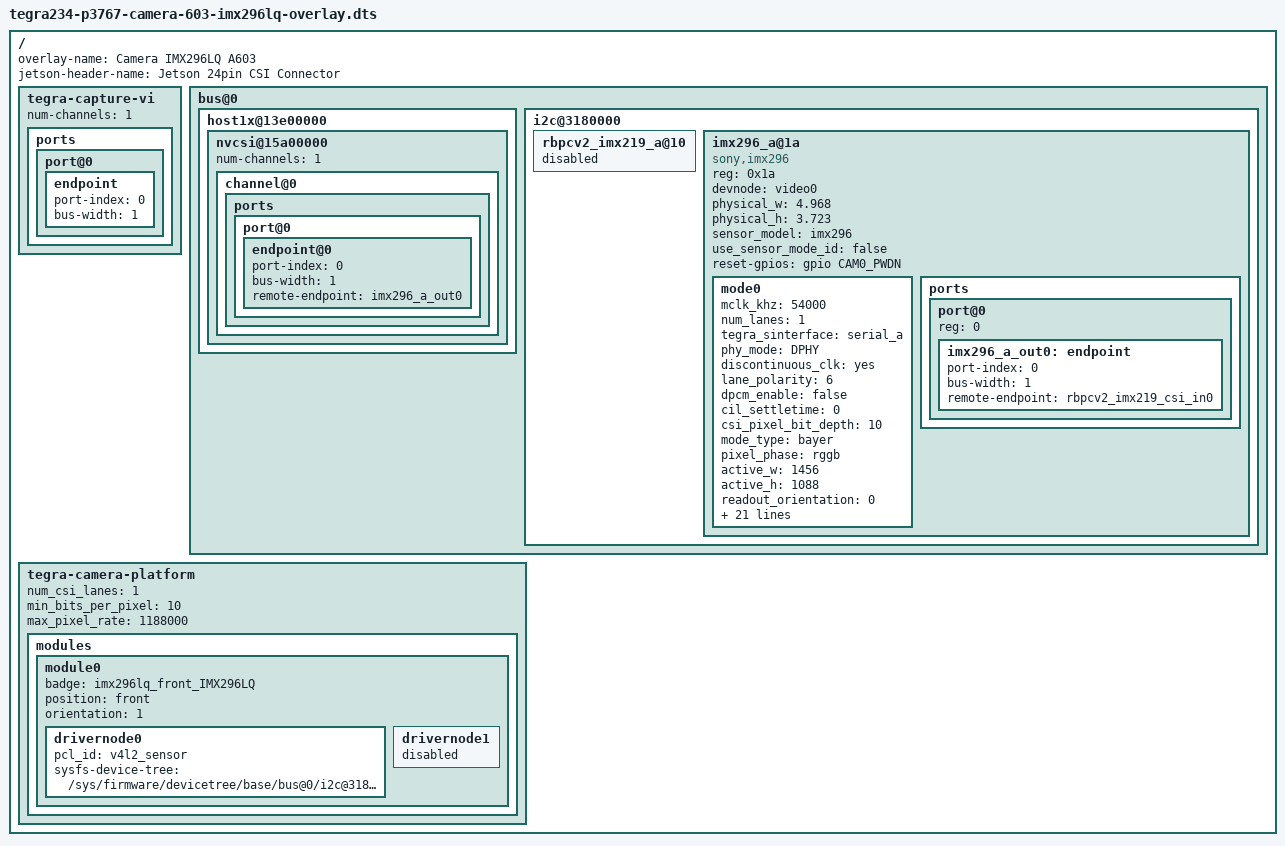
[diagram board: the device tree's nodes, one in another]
// SPDX-License-Identifier: GPL-2.0-only
// Sony IMX296LQ (color, global shutter) on Leetop / Seeed A603 15-pin CSI.
//
// Camera-module 15-pin (Raspberry-Pi CSI pinout, confirmed from the module):
//   1  GND
//   2  MDN0     CSI data lane 0 -
//   3  MDP0     CSI data lane 0 +
//   4  GND
//   5  MDN1     unused (IMX296 is 1-lane CSI-2)
//   6  MDP1     unused
//   7  GND
//   8  MCN      CSI clock -
//   9  MCP      CSI clock +
//  10  GND
//  11  PWDN     XCLR / power-down, Tegra main GPIO H.6
//               Live A603: PH.06 high -> I2C 0x1a appears; PH.06 low -> NACK.
//  12  NC       no host MCLK / LED; sensor uses its own 54 MHz oscillator
//  13  SIO-C    I2C SCL  (cam_i2c / i2c@3180000)
//  14  SIO-D    I2C SDA
//  15  +3.3V
//
// A603 already bakes a 2-lane IMX219 into the base DTB on the same connector.
// This overlay disables that IMX219 node, retargets CSI A to 1-lane, and adds
// IMX296LQ at I2C 0x1a. Labels (&gpio, &rbpcv2_imx219_csi_in0) resolve against
// the A603 base DTB __symbols__.
//
// Do not touch the A603 cam0-rst hog on PH.03. That pin is not the 15-pin
// camera PWDN. MB1 leaves PH.06 output-low; the IMX296 driver releases it.
//
// lane_polarity=6 matches the A603 IMX219 topology on serial_a (lane0 inverted).
// If the first capture is garbled, try 0 / 2 / 4 before changing anything else.

/dts-v1/;
/plugin/;

#define CAM0_PWDN	TEGRA234_MAIN_GPIO(H, 6)

#include <dt-bindings/tegra234-p3767-0000-common.h>

/ {
	overlay-name = "Camera IMX296LQ A603";
	jetson-header-name = "Jetson 24pin CSI Connector";
	compatible = JETSON_COMPATIBLE_P3768;

	fragment-camera-imx296lq-a603@0 {
		target-path = "/";
		__overlay__ {

			tegra-capture-vi {
				num-channels = <1>;
				ports {
					port@0 {
						endpoint {
							port-index = <0>;
							bus-width = <1>;
						};
					};
				};
			};

			bus@0 {
				host1x@13e00000 {
					nvcsi@15a00000 {
						num-channels = <1>;
						channel@0 {
							ports {
								port@0 {
									endpoint@0 {
										port-index = <0>;
										bus-width = <1>;
										remote-endpoint = <&imx296_a_out0>;
									};
								};
							};
						};
					};
				};

				i2c@3180000 {
					#address-cells = <1>;
					#size-cells = <0>;
					status = "okay";

					rbpcv2_imx219_a@10 {
						status = "disabled";
					};

					imx296_a@1a {
						compatible = "sony,imx296";
						reg = <0x1a>;
						devnode = "video0";
						status = "okay";

						physical_w = "4.968";
						physical_h = "3.723";
						sensor_model = "imx296";
						use_sensor_mode_id = "false";

						/* Pin 11 PWDN = PH.06. Driver: 0=reset, 1=release. */
						reset-gpios = <&gpio CAM0_PWDN GPIO_ACTIVE_HIGH>;

						mode0 {
							mclk_khz = "54000";
							num_lanes = "1";
							tegra_sinterface = "serial_a";
							phy_mode = "DPHY";

							discontinuous_clk = "yes";
							lane_polarity = "6";
							dpcm_enable = "false";
							cil_settletime = "0";

							csi_pixel_bit_depth = "10";
							mode_type = "bayer";
							pixel_phase = "rggb";

							active_w = "1456";
							active_h = "1088";
							readout_orientation = "0";

							line_length = "1760";
							inherent_gain = "1";
							pix_clk_hz = "118800000";

							gain_factor = "1";
							min_gain_val = "0";
							max_gain_val = "480";
							step_gain_val = "1";
							default_gain = "0";

							min_hdr_ratio = "1";
							max_hdr_ratio = "1";

							framerate_factor = "1000000";
							min_framerate = "1000000";
							max_framerate = "60000000";
							step_framerate = "1";
							default_framerate = "60000000";

							exposure_factor = "1000000";
							min_exp_time = "15";
							max_exp_time = "15699";
							step_exp_time = "1";
							default_exp_time = "10000";

							embedded_metadata_height = "2";
						};

						ports {
							#address-cells = <1>;
							#size-cells = <0>;
							port@0 {
								reg = <0>;
								imx296_a_out0: endpoint {
									status = "okay";
									port-index = <0>;
									bus-width = <1>;
									remote-endpoint = <&rbpcv2_imx219_csi_in0>;
								};
							};
						};
					};
				};
			};

			tegra-camera-platform {
				num_csi_lanes = <1>;
				min_bits_per_pixel = <10>;
				max_pixel_rate = <1188000>;

				modules {
					module0 {
						badge = "imx296lq_front_IMX296LQ";
						position = "front";
						orientation = "1";

						drivernode0 {
							pcl_id = "v4l2_sensor";
							sysfs-device-tree = "/sys/firmware/devicetree/base/bus@0/i2c@3180000/imx296_a@1a";
						};

						drivernode1 {
							status = "disabled";
						};
					};
				};
			};
		};
	};
};
